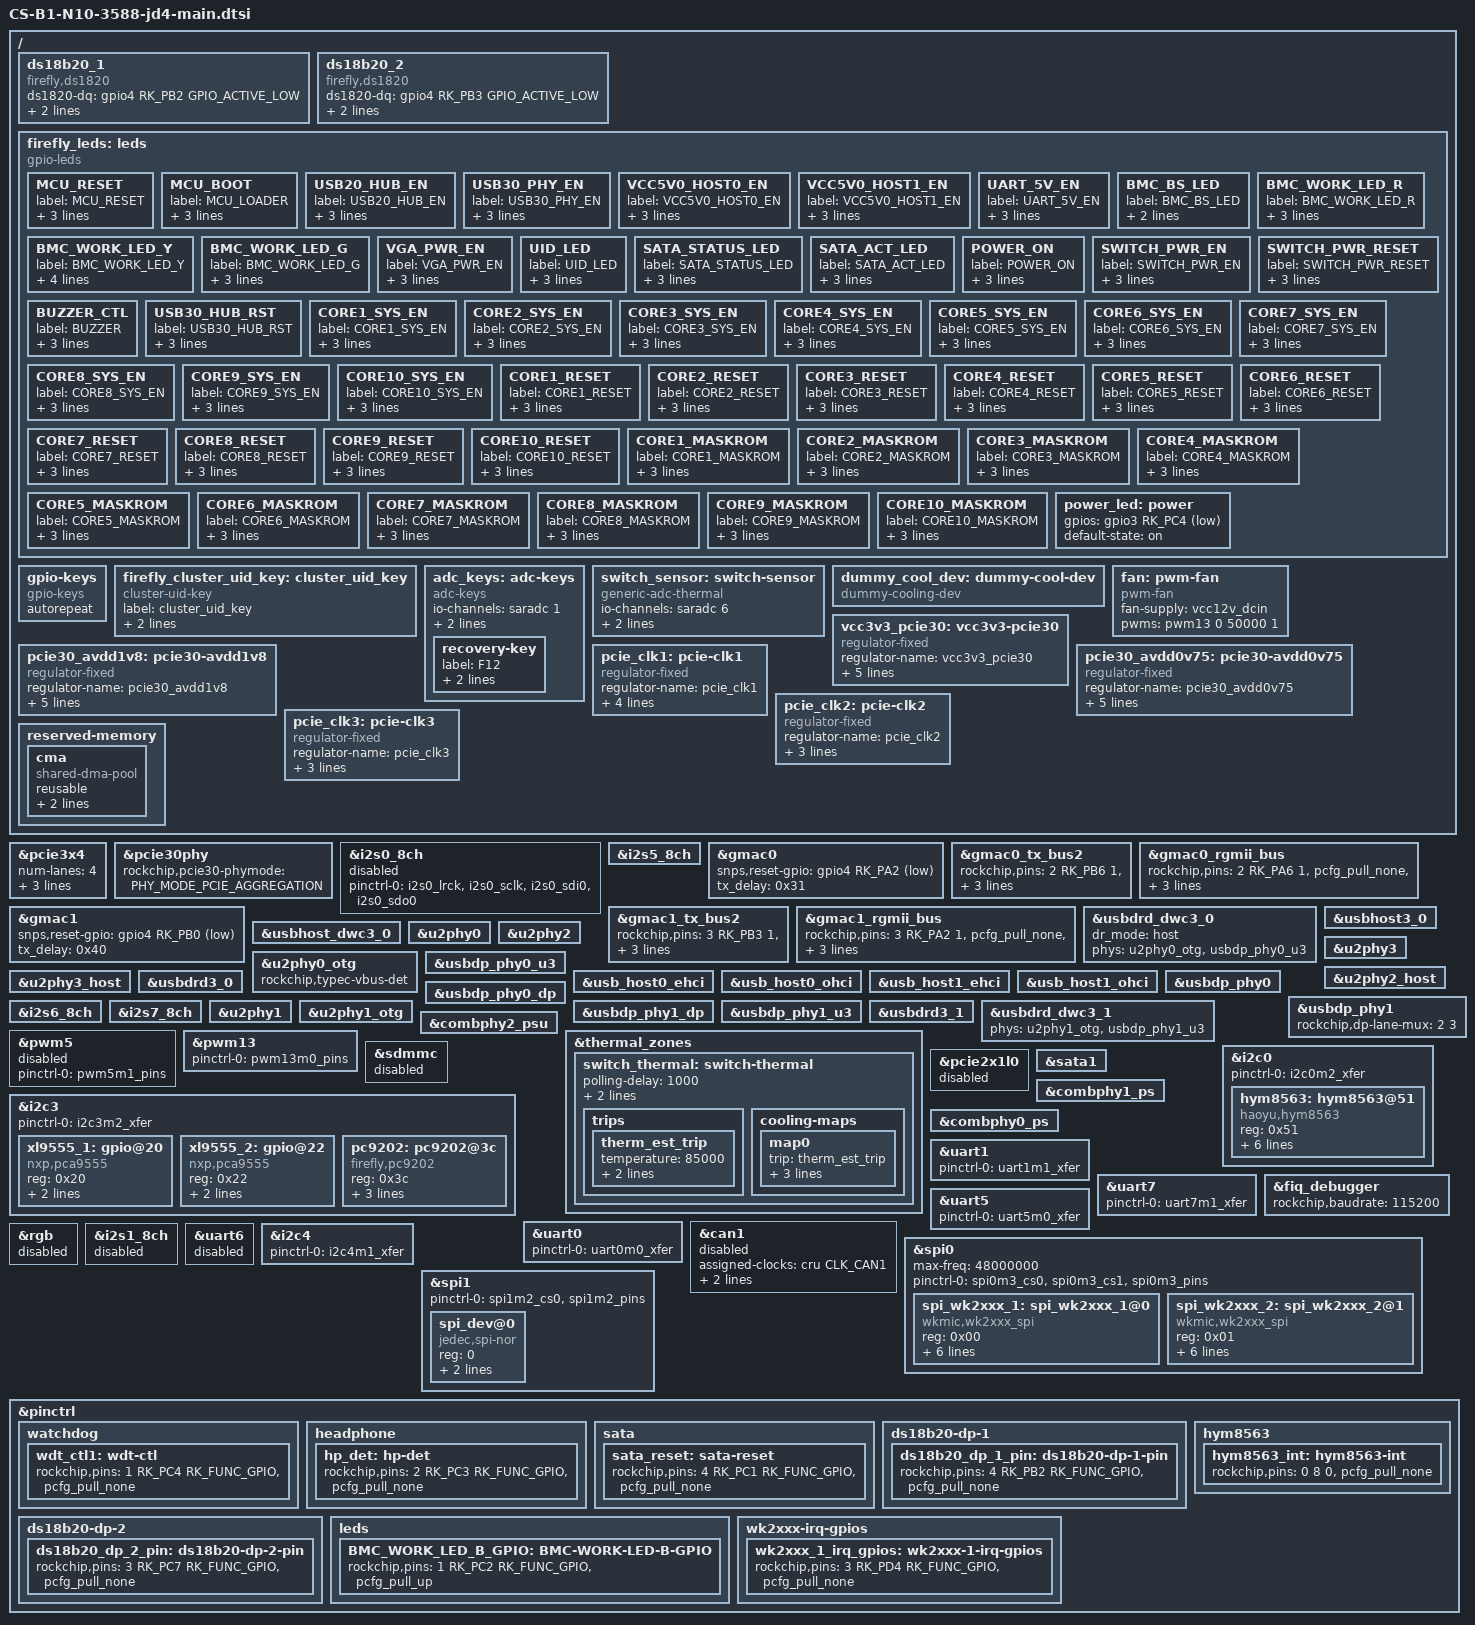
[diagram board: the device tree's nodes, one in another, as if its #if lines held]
// SPDX-License-Identifier: (GPL-2.0+ OR MIT)
/*
 * Copyright (c) 2021 Rockchip Electronics Co., Ltd.
 *
 */

#include <dt-bindings/leds/common.h>
#include "rk3588-firefly-common.dtsi"


 / {
#ifdef FF_OTHER
	/delete-node/ es8388_sound;
#endif

#ifdef FF_DS18B20
	ds18b20_1 {
		// Front sersonr
		compatible = "firefly,ds1820";
		status = "okay";
		ds1820-dq = <&gpio4 RK_PB2 GPIO_ACTIVE_LOW>; //GPIO4_B2 TEMP_DET_1
		ds18b20-id = <1>;
		pinctrl-names = "default";
		pinctrl-0 = <&ds18b20_dp_1_pin>;
	};

	ds18b20_2 {
		compatible = "firefly,ds1820";
		ds1820-dq = <&gpio4 RK_PB3 GPIO_ACTIVE_LOW>; //GPIO4_B3 TEMP_DET_2
		ds18b20-id = <2>;
		status = "okay";
		pinctrl-names = "default";
		pinctrl-0 = <&ds18b20_dp_2_pin>;
	};
#endif

#ifdef FF_LEDS
	leds {
		compatible = "gpio-leds";
		status = "okay";
		/delete-node/ user;

		// PW_OK {
		// 	label = "PW_OK";
		// 	gpios = <&gpio0 RK_PC7 GPIO_ACTIVE_HIGH>;	//GPIO0_C7
		// 	default-state = "on";
		// 	retain-state-shutdown;
		// };

		MCU_RESET {
			label = "MCU_RESET";
			gpios = <&gpio4 RK_PC6 GPIO_ACTIVE_HIGH>;	//GPIO4_C6
			default-state = "off";
			retain-state-shutdown;
		};

		MCU_BOOT {
			label = "MCU_LOADER";
			gpios = <&gpio4 RK_PA3 GPIO_ACTIVE_HIGH>;	//GPIO4_A3
			default-state = "off";
			retain-state-shutdown;
		};

		USB20_HUB_EN {
			label = "USB20_HUB_EN";
			gpios = <&gpio1 RK_PC7 GPIO_ACTIVE_HIGH>;	//GPIO1_C7
			default-state = "on";
			retain-state-shutdown;
		};

		USB30_PHY_EN {
			label = "USB30_PHY_EN";
			gpios = <&gpio1 RK_PD4 GPIO_ACTIVE_HIGH>;	//GPIO1_D4
			default-state = "on";
			retain-state-shutdown;
		};

		VCC5V0_HOST0_EN {
			label = "VCC5V0_HOST0_EN";
			gpios = <&gpio1 RK_PC5 GPIO_ACTIVE_HIGH>;	//GPIO1_C5
			default-state = "on";
			retain-state-shutdown;
		};

		VCC5V0_HOST1_EN {
			label = "VCC5V0_HOST1_EN";
			gpios = <&gpio1 RK_PC3 GPIO_ACTIVE_HIGH>;	//GPIO1_C3
			default-state = "on";
			retain-state-shutdown;
		};

		UART_5V_EN {
			label = "UART_5V_EN";
			gpios = <&gpio1 RK_PD7 GPIO_ACTIVE_HIGH>;	//GPIO1_D7
			default-state = "on";
			retain-state-shutdown;
		};

		BMC_BS_LED {
			label = "BMC_BS_LED";
			gpios = <&gpio1 RK_PA4 GPIO_ACTIVE_LOW>;	//GPIO1_A4
			default-state = "on";
			// retain-state-shutdown;
			pinctrl-names = "default";
			// pinctrl-0 = <&BMC_WORK_LED_B_GPIO>;
		};

		BMC_WORK_LED_R {
			label = "BMC_WORK_LED_R";
			gpios = <&gpio1 RK_PC2 GPIO_ACTIVE_HIGH>;	//GPIO1_C2
			default-state = "off";
			retain-state-shutdown;
			pinctrl-names = "default";
			// pinctrl-0 = <&BMC_WORK_LED_B_GPIO>;
		};

		BMC_WORK_LED_Y {
			label = "BMC_WORK_LED_Y";
			linux,default-trigger = "heartbeat";
			gpios = <&gpio3 RK_PA6 GPIO_ACTIVE_HIGH>;	//GPIO3_A6
			default-state = "on";
			retain-state-shutdown;
		};

		BMC_WORK_LED_G {
			label = "BMC_WORK_LED_G";
			gpios = <&gpio1 RK_PA6 GPIO_ACTIVE_HIGH>;	//GPIO1_A5
			default-state = "off";
			retain-state-shutdown;
		};


		VGA_PWR_EN {
			label = "VGA_PWR_EN";
			gpios = <&gpio0 RK_PD3 GPIO_ACTIVE_HIGH>;	//GPIO0_D3
			default-state = "on";
			retain-state-shutdown;
		};

		UID_LED {
			label = "UID_LED";
			gpios = <&gpio1 RK_PD5 GPIO_ACTIVE_HIGH>;	//GPIO1_D5
			default-state = "off";
			retain-state-shutdown;
		};

		SATA_STATUS_LED {
			label = "SATA_STATUS_LED"; // yellow
			gpios = <&gpio1 RK_PA1 GPIO_ACTIVE_HIGH>;	//GPIO1_A1
			default-state = "off";
			retain-state-shutdown;
		};

		SATA_ACT_LED {
			label = "SATA_ACT_LED"; // green
			gpios = <&gpio1 RK_PA0 GPIO_ACTIVE_HIGH>;   //GPIO1_A0
			default-state = "off";
			retain-state-shutdown;
		};

		POWER_ON {
			label = "POWER_ON";
			gpios = <&xl9555_1 PCA_IO0_5 GPIO_ACTIVE_HIGH>;	//PCA9555_1 PCA_IO0_5
			default-state = "keep";
			retain-state-shutdown;
		};

		SWITCH_PWR_EN {
			label = "SWITCH_PWR_EN";
			gpios = <&gpio2 RK_PC3 GPIO_ACTIVE_LOW>;	//GPIO2_C3
			default-state = "keep";
			retain-state-shutdown;
		};

		SWITCH_PWR_RESET {
			label = "SWITCH_PWR_RESET";
			gpios = <&gpio4 RK_PC3 GPIO_ACTIVE_HIGH>;	//GPIO4_C3
			default-state = "off";
			retain-state-shutdown;
		};

		BUZZER_CTL {
			label = "BUZZER";
			gpios = <&gpio1 RK_PA3 GPIO_ACTIVE_HIGH>;	//GPIO1_A3
			default-state = "off";
			retain-state-shutdown;
		};

		USB30_HUB_RST {
			label = "USB30_HUB_RST";
			gpios = <&gpio1 RK_PA2 GPIO_ACTIVE_HIGH>;	//GPIO1_A2
			default-state = "off";
			retain-state-shutdown;
		};

		CORE1_SYS_EN {
			label = "CORE1_SYS_EN";
			gpios = <&xl9555_1 PCA_IO0_0 GPIO_ACTIVE_HIGH>;
			default-state = "keep";
			retain-state-shutdown;
		};

		CORE2_SYS_EN {
			label = "CORE2_SYS_EN";
			gpios = <&xl9555_1 PCA_IO0_1 GPIO_ACTIVE_HIGH>;
			default-state = "keep";
			retain-state-shutdown;
		};

		CORE3_SYS_EN {
			label = "CORE3_SYS_EN";
			gpios = <&xl9555_1 PCA_IO0_2 GPIO_ACTIVE_HIGH>;
			default-state = "keep";
			retain-state-shutdown;
		};

		CORE4_SYS_EN {
			label = "CORE4_SYS_EN";
			gpios = <&xl9555_1 PCA_IO0_3 GPIO_ACTIVE_HIGH>;
			default-state = "keep";
			retain-state-shutdown;
		};

		CORE5_SYS_EN {
			label = "CORE5_SYS_EN";
			gpios = <&xl9555_1 PCA_IO0_4 GPIO_ACTIVE_HIGH>;
			default-state = "keep";
			retain-state-shutdown;
		};

		CORE6_SYS_EN {
			label = "CORE6_SYS_EN";
			gpios = <&xl9555_2 PCA_IO0_0 GPIO_ACTIVE_HIGH>;
			default-state = "keep";
			retain-state-shutdown;
		};

		CORE7_SYS_EN {
			label = "CORE7_SYS_EN";
			gpios = <&xl9555_2 PCA_IO0_1 GPIO_ACTIVE_HIGH>;
			default-state = "keep";
			retain-state-shutdown;
		};

		CORE8_SYS_EN {
			label = "CORE8_SYS_EN";
			gpios = <&xl9555_2 PCA_IO0_2 GPIO_ACTIVE_HIGH>;
			default-state = "keep";
			retain-state-shutdown;
		};

		CORE9_SYS_EN {
			label = "CORE9_SYS_EN";
			gpios = <&xl9555_2 PCA_IO0_3 GPIO_ACTIVE_HIGH>;
			default-state = "keep";
			retain-state-shutdown;
		};

		CORE10_SYS_EN {
			label = "CORE10_SYS_EN";
			gpios = <&xl9555_2 PCA_IO0_4 GPIO_ACTIVE_HIGH>;
			default-state = "keep";
			retain-state-shutdown;
		};

		CORE1_RESET {
			label = "CORE1_RESET";
			gpios = <&xl9555_1 PCA_IO1_1 GPIO_ACTIVE_HIGH>;
			default-state = "off";
			retain-state-shutdown;
		};

		CORE2_RESET {
			label = "CORE2_RESET";
			gpios = <&xl9555_1 PCA_IO1_2 GPIO_ACTIVE_HIGH>;
			default-state = "off";
			retain-state-shutdown;
		};

		CORE3_RESET {
			label = "CORE3_RESET";
			gpios = <&xl9555_1 PCA_IO1_3 GPIO_ACTIVE_HIGH>;
			default-state = "off";
			retain-state-shutdown;
		};

		CORE4_RESET {
			label = "CORE4_RESET";
			gpios = <&xl9555_1 PCA_IO1_4 GPIO_ACTIVE_HIGH>;
			default-state = "off";
			retain-state-shutdown;
		};

		CORE5_RESET {
			label = "CORE5_RESET";
			gpios = <&xl9555_1 PCA_IO1_5 GPIO_ACTIVE_HIGH>;
			default-state = "off";
			retain-state-shutdown;
		};

		CORE6_RESET {
			label = "CORE6_RESET";
			gpios = <&xl9555_2 PCA_IO0_6 GPIO_ACTIVE_HIGH>;
			default-state = "off";
			retain-state-shutdown;
		};

		CORE7_RESET {
			label = "CORE7_RESET";
			gpios = <&xl9555_2 PCA_IO0_7 GPIO_ACTIVE_HIGH>;
			default-state = "off";
			retain-state-shutdown;
		};

		CORE8_RESET {
			label = "CORE8_RESET";
			gpios = <&xl9555_2 PCA_IO1_0 GPIO_ACTIVE_HIGH>;
			default-state = "off";
			retain-state-shutdown;
		};

		CORE9_RESET {
			label = "CORE9_RESET";
			gpios = <&xl9555_2 PCA_IO1_1 GPIO_ACTIVE_HIGH>;
			default-state = "off";
			retain-state-shutdown;
		};

		CORE10_RESET {
			label = "CORE10_RESET";
			gpios = <&xl9555_2 PCA_IO1_2 GPIO_ACTIVE_HIGH>;
			default-state = "off";
			retain-state-shutdown;
		};

		CORE1_MASKROM {
			label = "CORE1_MASKROM";
			gpios = <&xl9555_1 PCA_IO0_6 GPIO_ACTIVE_HIGH>;
			default-state = "off";
			retain-state-shutdown;
		};

		CORE2_MASKROM {
			label = "CORE2_MASKROM";
			gpios = <&xl9555_1 PCA_IO0_7 GPIO_ACTIVE_HIGH>;
			default-state = "off";
			retain-state-shutdown;
		};

		CORE3_MASKROM {
			label = "CORE3_MASKROM";
			gpios = <&xl9555_1 PCA_IO1_0 GPIO_ACTIVE_HIGH>;
			default-state = "off";
			retain-state-shutdown;
		};

		CORE4_MASKROM {
			label = "CORE4_MASKROM";
			gpios = <&xl9555_1 PCA_IO1_6 GPIO_ACTIVE_HIGH>;
			default-state = "off";
			retain-state-shutdown;
		};

		CORE5_MASKROM {
			label = "CORE5_MASKROM";
			gpios = <&xl9555_1 PCA_IO1_7 GPIO_ACTIVE_HIGH>;
			default-state = "off";
			retain-state-shutdown;
		};

		CORE6_MASKROM {
			label = "CORE6_MASKROM";
			gpios = <&xl9555_2 PCA_IO1_3 GPIO_ACTIVE_HIGH>;
			default-state = "off";
			retain-state-shutdown;
		};

		CORE7_MASKROM {
			label = "CORE7_MASKROM";
			gpios = <&xl9555_2 PCA_IO1_4 GPIO_ACTIVE_HIGH>;
			default-state = "off";
			retain-state-shutdown;
		};

		CORE8_MASKROM {
			label = "CORE8_MASKROM";
			gpios = <&xl9555_2 PCA_IO1_5 GPIO_ACTIVE_HIGH>;
			default-state = "off";
			retain-state-shutdown;
		};

		CORE9_MASKROM {
			label = "CORE9_MASKROM";
			gpios = <&xl9555_2 PCA_IO1_6 GPIO_ACTIVE_HIGH>;
			default-state = "off";
			retain-state-shutdown;
		};

		CORE10_MASKROM {
			label = "CORE10_MASKROM";
			gpios = <&xl9555_2 PCA_IO1_7 GPIO_ACTIVE_HIGH>;
			default-state = "off";
			retain-state-shutdown;
		};
	};
	firefly_leds: leds {
		power_led: power {
			gpios = <&gpio3 RK_PC4 GPIO_ACTIVE_LOW>;//green led
            default-state = "on";
		};
	};
#endif

#ifdef FF_KEYS
	gpio-keys {
		compatible = "gpio-keys";
		autorepeat;
	};

	//uid key to recovery
	firefly_cluster_uid_key:cluster_uid_key {
		label = "cluster_uid_key";
		compatible = "cluster-uid-key";
		cluster_uid_gpio = <&gpio4 RK_PD2 GPIO_ACTIVE_HIGH>;
		status = "okay";
	};
	adc_keys: adc-keys {
		status = "okay";
		compatible = "adc-keys";
		io-channels = <&saradc 1>;
		io-channel-names = "buttons";
		keyup-threshold-microvolt = <1800000>;
		poll-interval = <100>;

		recovery-key{
			label = "F12";
			linux,code = <KEY_F12>;
			press-threshold-microvolt = <17000>;
		};
	};
#endif

#ifdef FF_COOL
	switch_sensor: switch-sensor {
        compatible = "generic-adc-thermal";
        #thermal-sensor-cells = <0>;
        io-channels = <&saradc 6>;
        io-channel-names = "sensor-channel";
        temperature-lookup-table = <
		           1000  1250 2000  1237 3000  1225 4000  1211 5000  1198 6000  1185 7000  1171 8000  1158 9000  1145
		10000 1131 11000 1117 12000 1103 13000 1089 14000 1074 15000 1060 16000 1046 17000 1031 18000 1017 19000 1002
		20000 987  21000 973  22000 958  23000 943  24000 928  25000 913  26000 899  27000 884  28000 869  29000 854
		30000 840  31000 825  32000 810  33000 795  34000 781  35000 766  36000 752  37000 728  38000 723  39000 709
		40000 695  41000 681  42000 667  43000 653  44000 640  45000 626  46000 613  47000 599  48000 586  49000 573
		50000 560  51000 548  52000 535  53000 523  54000 511  55000 499  56000 487  57000 476  58000 464  59000 453
		60000 422  61000 431  62000 420  63000 410  64000 399  65000 389  66000 379  67000 369  68000 360  69000 350
		70000 341  71000 332  72000 324  73000 315  74000 306  75000 298  76000 290  77000 282  78000 274  79000 266
		80000 259  81000 252  82000 245  83000 238  84000 231  85000 225  86000 218  87000 212  88000 206  89000 200
		90000 194  91000 189  92000 183  93000 178  94000 172  95000 167  96000 163  97000 158  98000 153  99000 149
		100000 144>;
	};

	dummy_cool_dev: dummy-cool-dev {
        compatible = "dummy-cooling-dev";
        #cooling-cells = <2>; /* min followed by max */
	};

	fan: pwm-fan {
		compatible = "pwm-fan";
		#cooling-cells = <2>;
		fan-supply = <&vcc12v_dcin>;
		pwms = <&pwm13 0 50000 1>;
	};

#endif

#ifdef FF_PCIE
	vcc3v3_pcie30: vcc3v3-pcie30 {
		compatible = "regulator-fixed";
		regulator-name = "vcc3v3_pcie30";
		regulator-min-microvolt = <3300000>;
		regulator-max-microvolt = <3300000>;
		enable-active-high;
		// gpios = <&gpio2 RK_PC5 GPIO_ACTIVE_HIGH>;
		startup-delay-us = <5000>;
		vin-supply = <&vcc12v_dcin>;
		status = "okay";
	};

	pcie30_avdd1v8: pcie30-avdd1v8 {
		compatible = "regulator-fixed";
		regulator-name = "pcie30_avdd1v8";
		regulator-boot-on;
		regulator-always-on;
		regulator-min-microvolt = <1800000>;
		regulator-max-microvolt = <1800000>;
		vin-supply = <&avcc_1v8_s0>;
	};

	pcie30_avdd0v75: pcie30-avdd0v75 {
		compatible = "regulator-fixed";
		regulator-name = "pcie30_avdd0v75";
		regulator-boot-on;
		regulator-always-on;
		regulator-min-microvolt = <750000>;
		regulator-max-microvolt = <750000>;
		vin-supply = <&avdd_0v75_s0>;
	};

	pcie_clk1: pcie-clk1 {
		compatible = "regulator-fixed";
		regulator-name = "pcie_clk1";
		regulator-boot-on;
		regulator-always-on;
		gpios = <&gpio3 RK_PC5 GPIO_ACTIVE_LOW>;
		vin-supply = <&vcc12v_dcin>;
		status = "okay";
	};

	pcie_clk2: pcie-clk2 {
		compatible = "regulator-fixed";
		regulator-name = "pcie_clk2";
		regulator-boot-on;
		regulator-always-on;
		gpios = <&gpio3 RK_PC6 GPIO_ACTIVE_LOW>;
		status = "okay";
	};

	pcie_clk3: pcie-clk3 {
		compatible = "regulator-fixed";
		regulator-name = "pcie_clk3";
		regulator-boot-on;
		regulator-always-on;
		gpios = <&gpio1 RK_PB1 GPIO_ACTIVE_LOW>;
		status = "okay";
	};
#endif

#ifdef FF_OTHER
	/* If hdmirx node is disabled, delete the reserved-memory node here. */
	reserved-memory {
		#address-cells = <2>;
		#size-cells = <2>;
		ranges;

		/* Reserve 256MB memory for hdmirx-controller@fdee0000 */
		cma {
			compatible = "shared-dma-pool";
			reusable;
			reg = <0x0 (256 * 0x100000) 0x0 (256 * 0x100000)>;
			linux,cma-default;
		};
	};
#endif
};

#ifdef FF_PCIE
&pcie3x4 {
	num-lanes = <4>;
	reset-gpios = <&gpio4 RK_PB6 GPIO_ACTIVE_HIGH>;
	vpcie3v3-supply = <&vcc3v3_pcie30>;
	// pinctrl-names = "default";
	// pinctrl-0 = <&pcie30x4m1_pins>;
	rockchip,perst-inactive-ms = <1000>;
	status = "okay";
};

&pcie30phy {
	// rockchip,pcie30-phymode = <PHY_MODE_PCIE_NABIBI>;
	rockchip,pcie30-phymode = <PHY_MODE_PCIE_AGGREGATION>;
	status = "okay";
};
#endif

#ifdef FF_OTHER
&i2s0_8ch {
	status = "disabled";
	pinctrl-0 = <&i2s0_lrck
				&i2s0_sclk
				&i2s0_sdi0
				&i2s0_sdo0>;
};

&i2s5_8ch {
	status = "okay";
};
#endif

#ifdef FF_GMAC0
&gmac0 {
	status = "okay";
	snps,reset-gpio = <&gpio4 RK_PA2 GPIO_ACTIVE_LOW>;
	tx_delay = <0x31>;
};

&gmac0_tx_bus2{
    rockchip,pins =
    /* gmac0_txd0 */
    <2 RK_PB6 1 &pcfg_pull_up_drv_level_6>,
    /* gmac0_txd1 */
    <2 RK_PB7 1 &pcfg_pull_up_drv_level_6>,
    /* gmac0_txen */
    <2 RK_PC0 1 &pcfg_pull_none>;
};

&gmac0_rgmii_bus{
        rockchip,pins =
        /* gmac0_rxd2 */
        <2 RK_PA6 1 &pcfg_pull_none>,
        /* gmac0_rxd3 */
        <2 RK_PA7 1 &pcfg_pull_none>,
        /* gmac0_txd2 */
        <2 RK_PB1 1 &pcfg_pull_up_drv_level_6>,
        /* gmac0_txd3 */
        <2 RK_PB2 1 &pcfg_pull_up_drv_level_6>;
};
#endif

#ifdef FF_GMAC1
&gmac1 {
        snps,reset-gpio = <&gpio4 RK_PB0 GPIO_ACTIVE_LOW>;
        tx_delay = <0x40>;
        status = "okay";
};

&gmac1_tx_bus2{
        rockchip,pins =
        /* gmac1_txd0 */
        <3 RK_PB3 1 &pcfg_pull_up_drv_level_6>,
    /* gmac1_txd1 */
        <3 RK_PB4 1 &pcfg_pull_up_drv_level_6>,
        /* gmac1_txen */
        <3 RK_PB5 1 &pcfg_pull_none>;
};

&gmac1_rgmii_bus{
        rockchip,pins =
        /* gmac1_rxd2 */
        <3 RK_PA2 1 &pcfg_pull_none>,
        /* gmac1_rxd3 */
        <3 RK_PA3 1 &pcfg_pull_none>,
        /* gmac1_txd2 */
        <3 RK_PA0 1 &pcfg_pull_up_drv_level_6>,
        /* gmac1_txd3 */
        <3 RK_PA1 1 &pcfg_pull_up_drv_level_6>;
};
#endif

#ifdef FF_USB
&usbdrd_dwc3_0 {
	dr_mode = "host";
	phys = <&u2phy0_otg>, <&usbdp_phy0_u3>;
	status = "okay";
};

&usbhost3_0 {
	status = "okay";
};

&usbhost_dwc3_0 {
	status = "okay";
};

&u2phy0 {
	status = "okay";
};

&u2phy2 {
	status = "okay";
};

&u2phy3 {
	status = "okay";
};

&u2phy0_otg {
	status = "okay";
	rockchip,typec-vbus-det;
};

&usbdp_phy0_u3 {
	status = "okay";
};

&u2phy2_host {
	status = "okay";
	/delete-property/ phy-supply;
};

&u2phy3_host {
	status = "okay";
	/delete-property/ phy-supply;
};

&usb_host0_ehci {
	status = "okay";
};

&usb_host0_ohci {
	status = "okay";
};

&usb_host1_ehci {
	status = "okay";
};

&usb_host1_ohci {
	status = "okay";
};


&usbdp_phy0 {
	status = "okay";
	// orientation-switch;
	// svid = <0xff01>;
	// sbu1-dc-gpios = <&gpio4 RK_PA6 GPIO_ACTIVE_HIGH>;
	// sbu2-dc-gpios = <&gpio4 RK_PA7 GPIO_ACTIVE_HIGH>;

	// port {
	// 	#address-cells = <1>;
	// 	#size-cells = <0>;
	// };
};

&usbdp_phy0_dp {
	status = "okay";
};

&usbdrd3_0 {
	status = "okay";
};

&usbdp_phy1 {
	rockchip,dp-lane-mux = <2 3>;
	status = "disabled";
};
#endif

&i2s6_8ch {
	status = "okay";
};

&i2s7_8ch {
	status = "okay";
};

#ifdef FF_USB_OTG
&u2phy1 {
	status = "okay";
};

&u2phy1_otg {
	/delete-property/ phy-supply;
	status = "okay";
};

&usbdp_phy1 {
	status = "okay";
};

&usbdp_phy1_dp {
	status = "okay";
};

&usbdp_phy1_u3 {
	status = "okay";
};

&usbdrd3_1 {
	status = "okay";
};

&usbdrd_dwc3_1 {
	status = "okay";
	phys = <&u2phy1_otg>, <&usbdp_phy1_u3>;
    status = "okay";
};

&combphy2_psu{
        status = "okay";
};

#endif


#ifdef FF_COOL
&pwm5 {
	pinctrl-0 = <&pwm5m1_pins>;
	status = "okay";
};

// fan
&pwm13 {
	pinctrl-0 = <&pwm13m0_pins>;
	status = "okay";
};
&thermal_zones {
	switch_thermal: switch-thermal {
		polling-delay = <1000>; /* milliseconds */
		polling-delay-passive = <1000>; /* milliseconds */
		thermal-sensors = <&switch_sensor>;

		trips {
			therm_est_trip: therm_est_trip {
				temperature = <85000>;
				type = "passive";
				hysteresis = <1000>;
			};
		};

		cooling-maps {
			map0 {
				trip = <&therm_est_trip>;
				cooling-device = <&dummy_cool_dev THERMAL_NO_LIMIT THERMAL_NO_LIMIT>;
				contribution = <100>;
			};

		};
	};
};
#endif

#ifdef FF_SDCARD
/* tf-card */
&sdmmc {
	status = "okay";
};
#endif

#ifdef FF_RTC
&i2c0 {
	status = "okay";
	pinctrl-names = "default";
	pinctrl-0 = <&i2c0m2_xfer>;
	// clock-frequency = <400000>;

	hym8563: hym8563@51 {
		status = "okay";
		compatible = "haoyu,hym8563";
		reg = <0x51>;
		#clock-cells = <0>;
		clock-frequency = <32768>;
		clock-output-names = "hym8563";
		pinctrl-names = "default";
		pinctrl-0 = <&hym8563_int>;
		interrupt-parent = <&gpio0>;
		interrupts = <8 8>;
		wakeup-source;
	};
};
#endif

#ifdef FF_PCA953X
&i2c3 {
	status = "okay";
	pinctrl-names = "default";
	pinctrl-0 = <&i2c3m2_xfer>;
	// clock-frequency = <400000>;

	/* XL9555*/
	xl9555_1: gpio@20 {
		status = "okay";
		compatible = "nxp,pca9555";
		reg = <0x20>;
		gpio-controller;
		#gpio-cells = <2>;
		gpio-group-num = <200>;
	};

	xl9555_2: gpio@22 {
		status = "okay";
		compatible = "nxp,pca9555";
		reg = <0x22>;
		gpio-controller;
		#gpio-cells = <2>;
		gpio-group-num = <300>;
	};
};
#endif

#ifdef FF_WATCHDOG
&i2c3 {
	status = "okay";
	pinctrl-names = "default";
	pinctrl-0 = <&i2c3m2_xfer>;
	// clock-frequency = <400000>;
	pc9202: pc9202@3c {
		status = "okay";
		compatible = "firefly,pc9202";
		reg = <0x3c>;
		wd-en-gpio = <&gpio1 RK_PC4 GPIO_ACTIVE_HIGH>;         // GPIO1_C4
		pinctrl-names = "default";
		pinctrl-0 = <&wdt_ctl1>;
		driver-names = "wdtdiban";
	};
};
#endif
#ifdef FF_SATA
// sata
&pcie2x1l0 {
	status = "disabled";
};

&sata1 {
	status = "okay";
};

&combphy1_ps {
	status = "okay";
};
// sata end

&combphy0_ps{
	status = "okay";
};
#endif


#ifdef FF_UART
/* RS485 */
&uart1{
	pinctrl-0 = <&uart1m1_xfer>;
	status = "okay";
};

/* RS232 */
&uart7{
	pinctrl-0 = <&uart7m1_xfer>;
	status = "okay";
};
//debug 115200 232
&fiq_debugger{
    rockchip,baudrate = <115200>;  /* Only 115200 and 1500000 */
};
// CORE10_DEBUG
&uart5 {
	status = "okay";
	pinctrl-0 = <&uart5m0_xfer>;
};
&uart0 {
	status = "okay";
	pinctrl-0 = <&uart0m0_xfer>;
};

#endif


#ifdef FF_OTHER
/* can1 */
&can1 {
	status = "disabled";
	assigned-clocks = <&cru CLK_CAN1>;
	assigned-clock-rates = <200000000>;
	pinctrl-names = "default";
	pinctrl-0 = <&can1m1_pins>;
};
&rgb {
	status = "disabled";
};
&i2s1_8ch {
	status = "disabled";
};

&sdmmc {
	status = "disabled";
};

&uart6 {
	status = "disabled";
};

&pwm5 {
//  pinctrl-0 = <&pwm5m1_pins>;
	status = "disabled";
};

&i2s0_8ch{
	status = "disabled";
};

// power
&i2c4 {
	status = "okay";
	pinctrl-names = "default";
	pinctrl-0 = <&i2c4m1_xfer>;
};
#endif

#ifdef FF_WK2XXX
&spi0 {
	status = "okay";
	max-freq = <48000000>;
	pinctrl-names = "default";
	pinctrl-0 = <&spi0m3_cs0 &spi0m3_cs1 &spi0m3_pins>;

	spi_wk2xxx_1: spi_wk2xxx_1@0{
		status = "okay";
		compatible = "wkmic,wk2xxx_spi";
		reg = <0x00>;
		index_base = <1>; // 偏移1，即从ttysWK1开始递增，而非ttysWK0
		num-ports = <4>;  // 4个串口模式
		spi-max-frequency = <10000000>;
		irq-gpio = <&gpio4 RK_PB1 IRQ_TYPE_EDGE_FALLING>;       // WK2124_INT   GPIO4_B1
		cs-gpio = <&gpio3 RK_PD4 GPIO_ACTIVE_HIGH>;
		firefly,spi0;
	};

	spi_wk2xxx_2: spi_wk2xxx_2@1{
		status = "okay";
		compatible = "wkmic,wk2xxx_spi";
		reg = <0x01>;
		index_base = <5>; // 偏移1，即从ttysWK1开始递增，而非ttysWK0
		num-ports = <4>;  // 4个串口模式
		spi-max-frequency = <10000000>;
#ifdef FF_HW_VERSION_V10
		irq-gpio = <&gpio4 RK_PB4 IRQ_TYPE_EDGE_FALLING>;       // WK2124_INT   GPIO4_B4
#endif
#ifdef FF_HW_VERSION_V11
		irq-gpio = <&gpio3 RK_PC7 IRQ_TYPE_EDGE_FALLING>;       // WK2124_INT   GPIO3_C7
#endif
		cs-gpio = <&gpio3 RK_PD5 GPIO_ACTIVE_HIGH>;
		firefly,spi0;
	};
};
#endif

#ifdef FF_SPI_FLASH
// spi flash
&spi1 {
	status = "okay";
	// max-freq = <48000000>;
	pinctrl-names = "default";
	pinctrl-0 = <&spi1m2_cs0 &spi1m2_pins>;

	spi_dev@0 {
		compatible = "jedec,spi-nor";
		reg = <0>;
		spi-max-frequency = <45000000>;
		spi-msb-first;
		// spi-cpol;
		// spi-cpha;
	};
};
#endif

/* pinctrl */
&pinctrl {
#ifdef FF_WATCHDOG
	watchdog {
		wdt_ctl1: wdt-ctl {
				rockchip,pins =
				<1 RK_PC4 RK_FUNC_GPIO &pcfg_pull_none>;            //GPIO1_C4
		};
	};
#endif

#ifdef FF_OTHER
	headphone {
		hp_det: hp-det {
			rockchip,pins = <2 RK_PC3 RK_FUNC_GPIO &pcfg_pull_none>;
		};
	};
#endif

#ifdef FF_SATA
	sata {
		sata_reset:sata-reset{
			rockchip,pins = <4 RK_PC1 RK_FUNC_GPIO &pcfg_pull_none>;
		};
	};
#endif

#ifdef FF_DS18B20
	ds18b20-dp-1 {
		ds18b20_dp_1_pin: ds18b20-dp-1-pin {
			rockchip,pins = <4 RK_PB2 RK_FUNC_GPIO &pcfg_pull_none>;  //GPIO4_B2
		};
	};

	ds18b20-dp-2 {
		ds18b20_dp_2_pin: ds18b20-dp-2-pin {
			rockchip,pins = <3 RK_PC7 RK_FUNC_GPIO &pcfg_pull_none>;  //GPIO4_B3
		};
	};
#endif

#ifdef FF_LEDS
    leds {
		BMC_WORK_LED_B_GPIO: BMC-WORK-LED-B-GPIO {
			/* led_power */
			rockchip,pins = <1 RK_PC2 RK_FUNC_GPIO &pcfg_pull_up>;
		};
 	};
#endif

#ifdef FF_WK2XXX
	wk2xxx-irq-gpios {
		wk2xxx_1_irq_gpios: wk2xxx-1-irq-gpios{
			rockchip,pins = <3 RK_PD4 RK_FUNC_GPIO &pcfg_pull_none>; // GPIO3_D4
		};

		// wk2xxx_2_irq_gpios: wk2xxx-2-irq-gpios{
		// 	rockchip,pins = <3 RK_PD5 RK_FUNC_GPIO &pcfg_pull_none>; // GPIO3_D5
		// };
	};
#endif

#ifdef FF_RTC
	hym8563 {
		hym8563_int: hym8563-int {
			rockchip,pins = <0 8 0 &pcfg_pull_none>;
		};
	};
#endif
};
